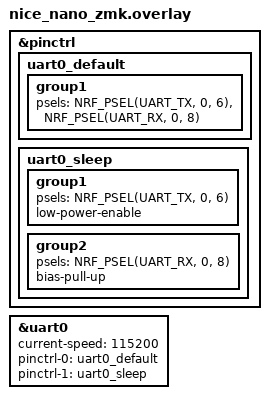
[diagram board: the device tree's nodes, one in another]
#include <zephyr/dt-bindings/pinctrl/nrf-pinctrl.h>

&pinctrl {
    uart0_default: uart0_default {
        group1 {
            psels = <NRF_PSEL(UART_TX, 0, 6)>,
                    <NRF_PSEL(UART_RX, 0, 8)>;
        };
    };

    uart0_sleep: uart0_sleep {
        group1 {
            /* TX can go low-power during sleep */
            psels = <NRF_PSEL(UART_TX, 0, 6)>;
            low-power-enable;
        };
        group2 {
            /* RX stays as input with pull-up so GPIO sense can fire on incoming data */
            psels = <NRF_PSEL(UART_RX, 0, 8)>;
            bias-pull-up;
        };
    };
};

&uart0 {
    status = "okay";
    current-speed = <115200>;
    pinctrl-0 = <&uart0_default>;
    pinctrl-1 = <&uart0_sleep>;
    pinctrl-names = "default", "sleep";
};
